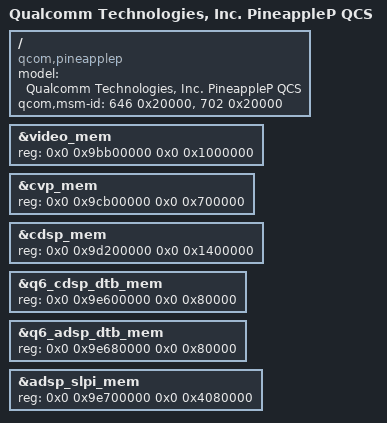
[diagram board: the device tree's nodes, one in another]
#include "pineapplep-v2.dtsi"

/ {
	model = "Qualcomm Technologies, Inc. PineappleP QCS";
	compatible = "qcom,pineapplep";
	qcom,msm-id = <646 0x20000>, <702 0x20000>;
};

&video_mem {
	reg = <0x0 0x9bb00000 0x0 0x1000000>;
};

&cvp_mem {
	reg = <0x0 0x9cb00000 0x0 0x700000>;
};

&cdsp_mem {
	reg = <0x0 0x9d200000 0x0 0x1400000>;
};

&q6_cdsp_dtb_mem {
	reg = <0x0 0x9e600000 0x0 0x80000>;
};

&q6_adsp_dtb_mem {
	reg = <0x0 0x9e680000 0x0 0x80000>;
};

&adsp_slpi_mem {
	reg = <0x0 0x9e700000 0x0 0x4080000>;
};

